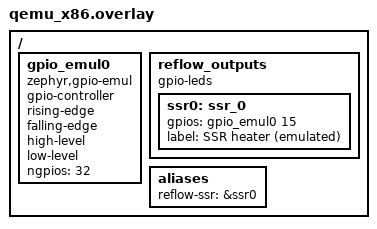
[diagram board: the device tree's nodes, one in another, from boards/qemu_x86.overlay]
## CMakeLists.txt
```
# SPDX-License-Identifier: Apache-2.0

cmake_minimum_required(VERSION 3.20.0)

# Reuse the application's own Kconfig instead of restating the CONFIG_REFLOW_*
# symbols heater.c needs. Restating them would let the test drift away from the
# defaults the firmware actually ships with, which is the opposite of what this
# suite is for. The application Kconfig ends with source "Kconfig.zephyr", so it
# is a complete root on its own.
set(KCONFIG_ROOT ${CMAKE_CURRENT_SOURCE_DIR}/../../Kconfig)

find_package(Zephyr REQUIRED HINTS $ENV{ZEPHYR_BASE})
project(reflow_boot_tests LANGUAGES C)

set(SRC ${CMAKE_CURRENT_SOURCE_DIR}/../../src)

# heater.c and nothing else: the point is that the SSR pin is safe with no
# control thread in the image at all. Linking controller.c would configure the
# pin from reflow_heater_init() and hide exactly what is being measured.
target_sources(app PRIVATE
  src/main.c
  ${SRC}/core/heater.c
)
target_include_directories(app PRIVATE ${SRC} ${SRC}/core)
```

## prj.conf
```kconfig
CONFIG_ZTEST=y
CONFIG_GPIO=y
CONFIG_GPIO_EMUL=y

# The control core is not in this image; the optional features must stay out too,
# or their Kconfig dependencies pull in subsystems this test has no board for.
CONFIG_REFLOW_SHELL=n
CONFIG_REFLOW_UI_DISPLAY=n
CONFIG_REFLOW_UI_INPUT=n
CONFIG_REFLOW_NET=n
```

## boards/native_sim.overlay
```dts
/*
 * SPDX-License-Identifier: Apache-2.0
 *
 * SIMULATION ONLY — nothing here describes hardware.
 *
 * `tests/boot` is its own Zephyr application, rooted at tests/boot, so it does
 * NOT see the application's boards/native_sim.overlay. Without this file the
 * alias 'reflow-ssr' does not exist on native_sim and heater.c stops the build
 * on its own guard — which would take down the `ztest (native_sim)` job, the one
 * that measures item 1 of the Definition of Done, the moment #59 is fixed.
 *
 * native_sim already provides a GPIO emulator as gpio0, so unlike the qemu_x86
 * overlay next to this one there is no controller to declare: only the SSR node
 * and the alias. Pin 15 and GPIO_ACTIVE_HIGH mirror the application's
 * boards/native_sim.overlay so both build the same shape.
 *
 * native_sim does not run on Windows (PROCESSO.md section 10), which is why the
 * qemu_x86 overlay exists as well. Both platforms build the same source and
 * assert the same thing; this one is what makes the suite measurable in CI.
 */

#include <zephyr/dt-bindings/gpio/gpio.h>

/ {
	reflow_outputs {
		compatible = "gpio-leds";

		ssr0: ssr_0 {
			gpios = <&gpio0 15 GPIO_ACTIVE_HIGH>;
			label = "SSR heater (emulated)";
		};
	};

	aliases {
		reflow-ssr = &ssr0;
	};
};
```

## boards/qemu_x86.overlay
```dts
/*
 * SPDX-License-Identifier: Apache-2.0
 *
 * SIMULATION ONLY — nothing here describes hardware. qemu_x86 has no GPIO
 * controller of its own, so this declares an emulated one and hangs the SSR
 * node off it, giving the suite somewhere to look for the gate.
 *
 * Why qemu_x86 at all, when native_sim already has an emulator: native_sim does
 * not run on Windows (twister filters it with "Native platform requires Linux",
 * PROCESSO.md section 10), and this suite has to be runnable on the machine the
 * firmware is developed on. Both platforms build the same source and assert the
 * same thing.
 */

#include <zephyr/dt-bindings/gpio/gpio.h>

/ {
	gpio_emul0: gpio_emul0 {
		compatible = "zephyr,gpio-emul";
		gpio-controller;
		rising-edge;
		falling-edge;
		high-level;
		low-level;
		#gpio-cells = <2>;
		ngpios = <32>;
		status = "okay";
	};

	reflow_outputs {
		compatible = "gpio-leds";

		ssr0: ssr_0 {
			gpios = <&gpio_emul0 15 GPIO_ACTIVE_HIGH>;
			label = "SSR heater (emulated)";
		};
	};

	aliases {
		reflow-ssr = &ssr0;
	};
};
```

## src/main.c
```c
/*
 * SPDX-License-Identifier: Apache-2.0
 *
 * RFO-T13, the part of it that does not need an oscilloscope.
 *
 * The bench test in RFO-T13 watches the real gate from power-on reset; that is
 * hardware work and this suite does not pretend to replace it. What it does
 * cover is the window the firmware is responsible for: from the moment the GPIO
 * controller exists until the control thread first runs. Before RFO-B06 nothing
 * claimed the pin in that window, so it sat as a high-impedance input for the
 * 100 ms K_THREAD_DEFINE delay, and an opto-coupled SSR with a pull-up on its
 * input reads high impedance as ON.
 *
 * The image deliberately contains heater.c and no control thread, so the only
 * thing that can have configured the pin by the time a test runs is the
 * SYS_INIT hook under test.
 */

#include <zephyr/device.h>
#include <zephyr/drivers/gpio.h>
#include <zephyr/drivers/gpio/gpio_emul.h>
#include <zephyr/ztest.h>

#define SSR_NODE DT_ALIAS(reflow_ssr)

static const struct gpio_dt_spec ssr = GPIO_DT_SPEC_GET(SSR_NODE, gpios);

/*
 * ztest runs at application level, after every SYS_INIT level has completed and
 * before anything in this image drives the heater. Whatever the pin looks like
 * here is what it looked like for the whole 100 ms the control thread used to
 * spend sleeping.
 */
ZTEST(reflow_boot, test_ssr_is_an_output_before_any_thread_runs)
{
	gpio_flags_t flags = 0;

	zassert_true(gpio_is_ready_dt(&ssr), "emulated gpio not ready");

	zassert_ok(gpio_emul_flags_get(ssr.port, ssr.pin, &flags),
		   "could not read the gate's configuration");

	/*
	 * This is the assertion that fails without the patch: an unclaimed pin
	 * has no GPIO_OUTPUT bit, which on real hardware is the high-impedance
	 * state the SSR module misreads as ON.
	 */
	zassert_true((flags & GPIO_OUTPUT) != 0,
		     "the gate is not driven at boot (flags 0x%x): high impedance "
		     "until the control thread starts",
		     (unsigned int)flags);
}

ZTEST(reflow_boot, test_ssr_is_low_before_any_thread_runs)
{
	int val = gpio_emul_output_get(ssr.port, ssr.pin);

	zassert_true(val >= 0, "could not read the gate: %d", val);
	zassert_equal(val, 0, "the gate is high at boot with no loop running");
}

/*
 * Sanity check on THIS SUITE'S OWN fixture, and nothing more.
 *
 * `ssr` comes from DT_ALIAS(reflow_ssr) resolved in the devicetree of this test
 * application — tests/boot/boards/<platform>.overlay. So what the assertion
 * guards is that the simulated overlay declares GPIO_ACTIVE_HIGH, which is what
 * makes the "physically low" reading in the test above meaningful. It says
 * nothing about the three board overlays: flipping the polarity in the Pico or
 * ESP32 overlay — the only ones where the mistake energises something real — is
 * invisible from here.
 *
 * The guarantee for the real targets is the BUILD_ASSERT on DT_GPIO_FLAGS in
 * heater.c, which resolves against the devicetree actually being built and so
 * fails the build on every board. Keep both: this one stops the fixture from
 * drifting out from under the test above, that one stops the boards.
 */
ZTEST(reflow_boot, test_inactive_means_physically_low)
{
	zassert_equal(ssr.dt_flags & GPIO_ACTIVE_LOW, 0,
		      "the SSR is declared active-low; GPIO_OUTPUT_INACTIVE would "
		      "then drive the gate high at boot");
}

ZTEST_SUITE(reflow_boot, NULL, NULL, NULL, NULL, NULL);
```
